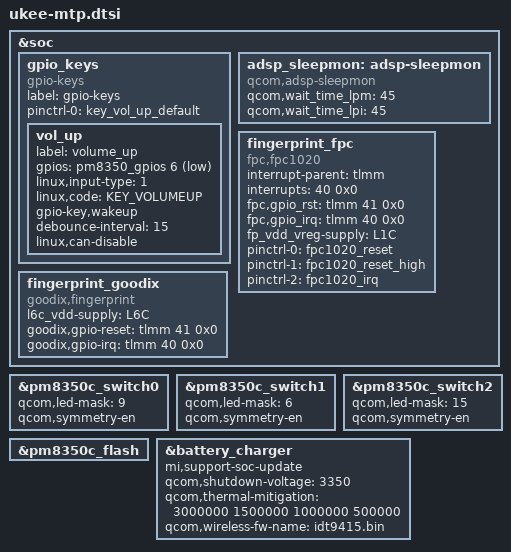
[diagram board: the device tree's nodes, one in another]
#include "cape-mtp.dtsi"
#include <dt-bindings/gpio/gpio.h>
#include <dt-bindings/input/input.h>

&soc {
	gpio_keys {
		compatible = "gpio-keys";
		label = "gpio-keys";

		pinctrl-names = "default";
		pinctrl-0 = <&key_vol_up_default>;

		vol_up {
			label = "volume_up";
			gpios = <&pm8350_gpios 6 GPIO_ACTIVE_LOW>;
			linux,input-type = <1>;
			linux,code = <KEY_VOLUMEUP>;
			gpio-key,wakeup;
			debounce-interval = <15>;
			linux,can-disable;
		};
	};

	adsp_sleepmon: adsp-sleepmon {
		compatible = "qcom,adsp-sleepmon";
		qcom,wait_time_lpm = <45>;
		qcom,wait_time_lpi = <45>;
	};

	fingerprint_fpc {
		status = "ok";
		compatible = "fpc,fpc1020";
		interrupt-parent = <&tlmm>;
		interrupts = <40 0x0>;
		fpc,gpio_rst = <&tlmm 41 0x0>;
		fpc,gpio_irq = <&tlmm 40 0x0>;
		fp_vdd_vreg-supply = <&L1C>;
		pinctrl-names = "fpc1020_reset_reset",
				"fpc1020_reset_active",
				"fpc1020_irq_active";

		pinctrl-0 = <&fpc1020_reset>;
		pinctrl-1 = <&fpc1020_reset_high>;
		pinctrl-2 = <&fpc1020_irq>;
	};

	fingerprint_goodix {
		status = "ok";
		compatible = "goodix,fingerprint";
		l6c_vdd-supply = <&L6C>;
		goodix,gpio-reset = <&tlmm 41 0x0>;
		goodix,gpio-irq = <&tlmm 40 0x0>;
	};
};

&pm8350c_switch0 {
	qcom,led-mask = <9>; /* Channels 1 & 4 */
	qcom,symmetry-en;
};

&pm8350c_switch1 {
	qcom,led-mask = <6>; /* Channels 2 & 3 */
	qcom,symmetry-en;
};

&pm8350c_switch2 {
	qcom,led-mask = <15>; /* All Channels */
	qcom,symmetry-en;
};

&pm8350c_flash {
	status = "ok";
};

&battery_charger {
	mi,support-soc-update;
	qcom,shutdown-voltage = <3350>;
	qcom,thermal-mitigation = <3000000 1500000 1000000 500000>;
	qcom,wireless-fw-name = "idt9415.bin";
};
